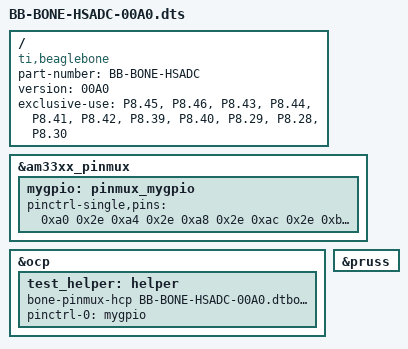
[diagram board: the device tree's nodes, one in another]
/*
* dts file BB-BONE-HSADC-00A0.dts
*/
/dts-v1/;
/plugin/;

/ {
  compatible = "ti,beaglebone", "ti,beaglebone-black";

  /* identification */
  part-number = "BB-BONE-HSADC";
  version = "00A0";

  exclusive-use =
    "P8.45",
    "P8.46",
    "P8.43",
    "P8.44",
    "P8.41",
    "P8.42",
    "P8.39",
    "P8.40",
    "P8.29",
    "P8.28",
    "P8.30";

  fragment@0 {
    target = <&am33xx_pinmux>;
    __overlay__ {
      mygpio: pinmux_mygpio{
        pinctrl-single,pins = <
          0xa0 0x2e
          0xa4 0x2e
          0xa8 0x2e
          0xac 0x2e
          0xb0 0x2e
          0xb4 0x2e
          0xb8 0x2e
          0xbc 0x2e
          0xe4 0x05
          0xe8 0x2e
          0xec 0x05
          >;
      };
    };
  };

  fragment@1 {
    target = <&ocp>;
    __overlay__ {
      test_helper: helper {
        compatible = "bone-pinmux-hcp BB-BONE-HSADC-00A0.dtbo /lib/firmware/elper";
        pinctrl-names = "default";
        pinctrl-0 = <&mygpio>;
        status = "okay";
      };
    };
  };

  fragment@2{
  target = <&pruss>;
    __overlay__ {
      status = "okay";
    };
  };
};
